# STM32L051T8Y7 register map
File version: 1.0
Registers are 32-bit, access not given, reset 0x0 unless marked. A register's access mark holds for its fields unless they carry their own. Offsets are from the block's base; [hi:lo] are bit positions; {n}, {i} and the like mark numbered series; 'fields as' and 'values as' point back to an identical list.

## LPTIM1
Base 0x40007C00
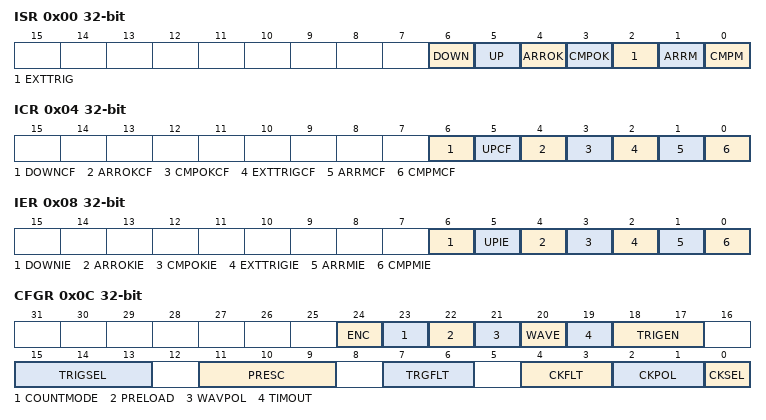
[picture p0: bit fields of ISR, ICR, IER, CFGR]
0x00 ISR
  [6] DOWN, [5] UP, [4] ARROK, [3] CMPOK, [2] EXTTRIG, [1] ARRM, [0] CMPM
0x04 ICR
  [6] DOWNCF, [5] UPCF, [4] ARROKCF, [3] CMPOKCF, [2] EXTTRIGCF, [1] ARRMCF, [0] CMPMCF
0x08 IER
  [6] DOWNIE, [5] UPIE, [4] ARROKIE, [3] CMPOKIE, [2] EXTTRIGIE, [1] ARRMIE, [0] CMPMIE
0x0C CFGR
  [24] ENC, [23] COUNTMODE, [22] PRELOAD, [21] WAVPOL, [20] WAVE, [19] TIMOUT, [18:17] TRIGEN, [15:13] TRIGSEL, [11:9] PRESC, [7:6] TRGFLT, [4:3] CKFLT, [2:1] CKPOL, [0] CKSEL
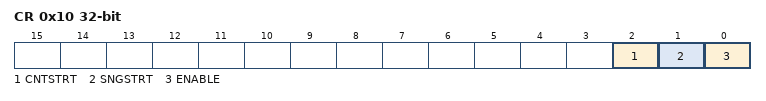
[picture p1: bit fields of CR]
0x10 CR
  [2] CNTSTRT, [1] SNGSTRT, [0] ENABLE
0x14 CMP
  [15:0] CMP
0x18 ARR
  [15:0] ARR
0x1C CNT
  [15:0] CNT

## SYSCFG
Base 0x40010000
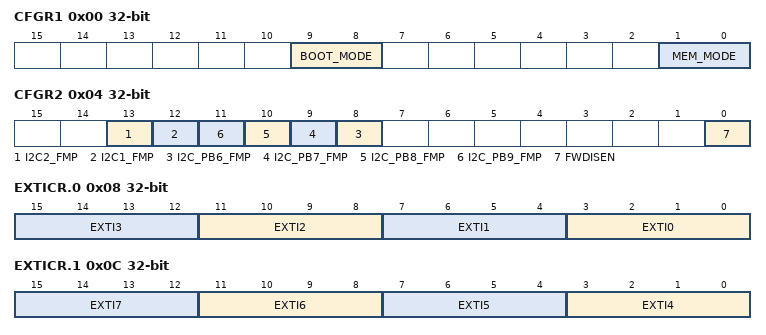
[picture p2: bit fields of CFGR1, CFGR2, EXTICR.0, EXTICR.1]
0x00 CFGR1
  [9:8] BOOT_MODE, [1:0] MEM_MODE
0x04 CFGR2
  [13] I2C2_FMP, [12] I2C1_FMP, [n+2] I2C_PB{n}_FMP (n=6..9), [0] FWDISEN
0x08 EXTICR.0
  [4n+3:4n] EXTI{n} (n=0..3)
0x0C EXTICR.1
  [4n-13:4n-16] EXTI{n} (n=4..7)
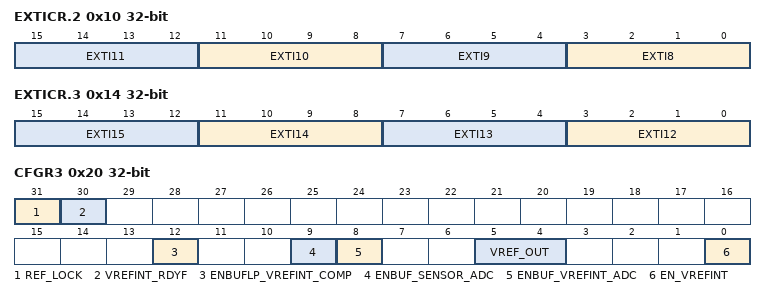
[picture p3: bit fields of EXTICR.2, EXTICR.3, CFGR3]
0x10 EXTICR.2
  [4n-29:4n-32] EXTI{n} (n=8..11)
0x14 EXTICR.3
  [4n-45:4n-48] EXTI{n} (n=12..15)
0x20 CFGR3
  [31] REF_LOCK, [30] VREFINT_RDYF, [12] ENBUFLP_VREFINT_COMP, [9] ENBUF_SENSOR_ADC, [8] ENBUF_VREFINT_ADC, [5:4] VREF_OUT, [0] EN_VREFINT

## COMP12_COMMON
Base 0x40010018
Same registers: COMP1 0x40010018
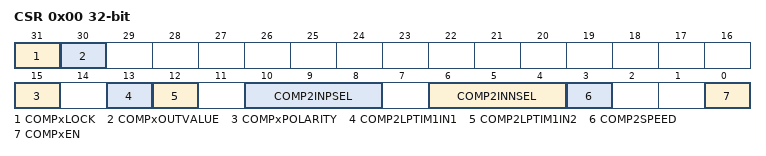
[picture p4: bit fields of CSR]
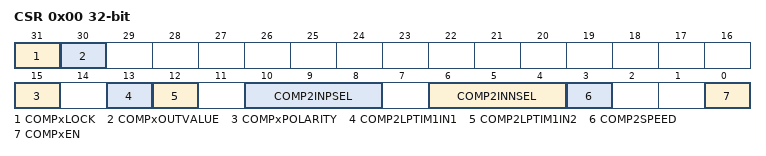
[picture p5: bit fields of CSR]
0x00 CSR
  [31] COMPxLOCK, [30] COMPxOUTVALUE, [15] COMPxPOLARITY, [13] COMP2LPTIM1IN1, [12] COMP2LPTIM1IN2, [10:8] COMP2INPSEL, [6:4] COMP2INNSEL, [3] COMP2SPEED, [0] COMPxEN

## COMP2
Base 0x4001001C
0x00 CSR
  [31] COMPxLOCK, [30] COMPxOUTVALUE, [15] COMPxPOLARITY, [13] COMP2LPTIM1IN1, [12] COMP2LPTIM1IN2, [10:8] COMP2INPSEL, [6:4] COMP2INNSEL, [3] COMP2SPEED, [0] COMPxEN

## EXTI
Base 0x40010400
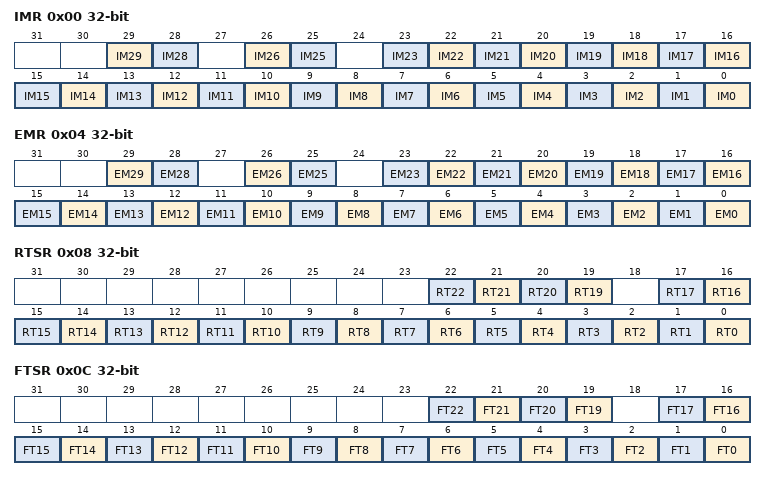
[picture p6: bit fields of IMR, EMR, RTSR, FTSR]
0x00 IMR
  [29] IM29, [28] IM28, [26] IM26, [25] IM25, [n] IM{n} (n=0..23)
0x04 EMR
  [29] EM29, [28] EM28, [26] EM26, [25] EM25, [n] EM{n} (n=0..23)
0x08 RTSR
  [n] RT{n} (n=19..22), [n] RT{n} (n=0..17)
0x0C FTSR
  [n] FT{n} (n=19..22), [n] FT{n} (n=0..17)
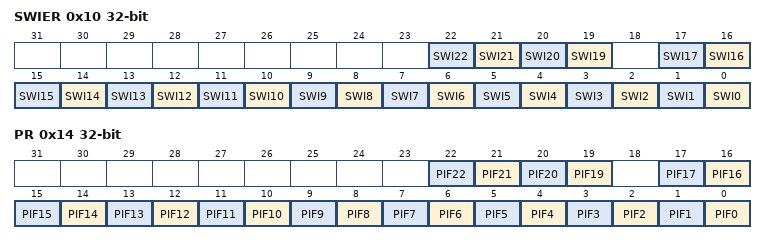
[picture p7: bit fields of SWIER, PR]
0x10 SWIER
  [n] SWI{n} (n=19..22), [n] SWI{n} (n=0..17)
0x14 PR
  [n] PIF{n} (n=19..22), [n] PIF{n} (n=0..17)

## FIREWALL
Base 0x40011C00
0x00 CSSA
0x04 CSL
0x08 NVDSSA
0x0C NVDSL
0x10 VDSSA
0x14 VDSL
0x18 LSSA
0x1C LSL
0x20 CR

## ADC1
Base 0x40012400
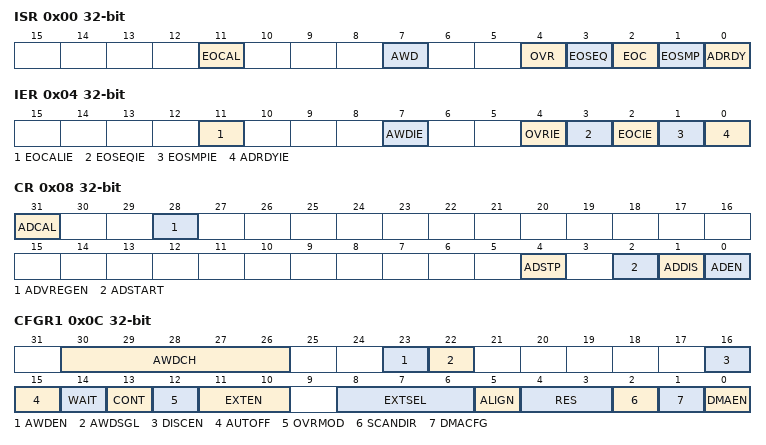
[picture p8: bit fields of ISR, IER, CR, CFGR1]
0x00 ISR
  [11] EOCAL, [7] AWD, [4] OVR, [3] EOSEQ, [2] EOC, [1] EOSMP, [0] ADRDY
0x04 IER
  [11] EOCALIE, [7] AWDIE, [4] OVRIE, [3] EOSEQIE, [2] EOCIE, [1] EOSMPIE, [0] ADRDYIE
0x08 CR
  [31] ADCAL, [28] ADVREGEN, [4] ADSTP, [2] ADSTART, [1] ADDIS, [0] ADEN
0x0C CFGR1
  [30:26] AWDCH, [23] AWDEN, [22] AWDSGL, [16] DISCEN, [15] AUTOFF, [14] WAIT, [13] CONT, [12] OVRMOD, [11:10] EXTEN, [8:6] EXTSEL, [5] ALIGN, [4:3] RES, [2] SCANDIR, [1] DMACFG, [0] DMAEN
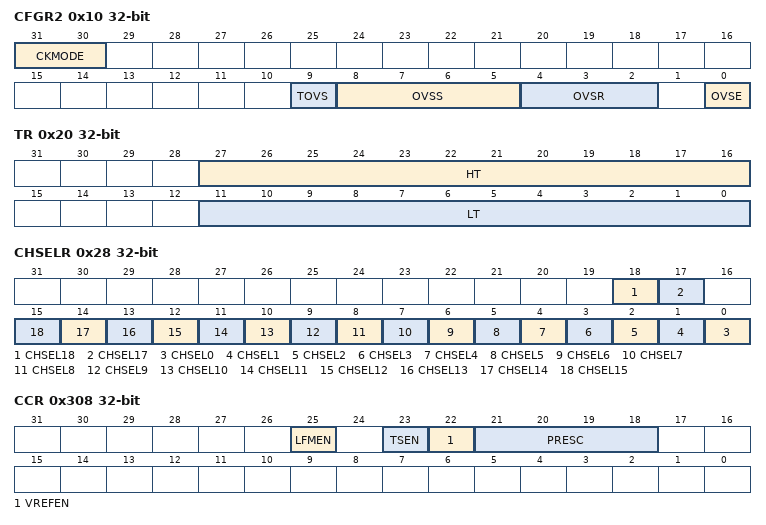
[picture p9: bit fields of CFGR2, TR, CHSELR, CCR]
0x10 CFGR2
  [31:30] CKMODE, [9] TOVS, [8:5] OVSS, [4:2] OVSR, [0] OVSE
0x14 SMPR
  [2:0] SMP
0x20 TR
  [27:16] HT, [11:0] LT
0x28 CHSELR
  [18] CHSEL18, [17] CHSEL17, [n] CHSEL{n} (n=0..15)
0x40 DR
  [15:0] DATA
0xB4 CALFACT
  [6:0] CALFACT
0x308 CCR
  [25] LFMEN, [23] TSEN, [22] VREFEN, [21:18] PRESC

## DMA1
Base 0x40020000
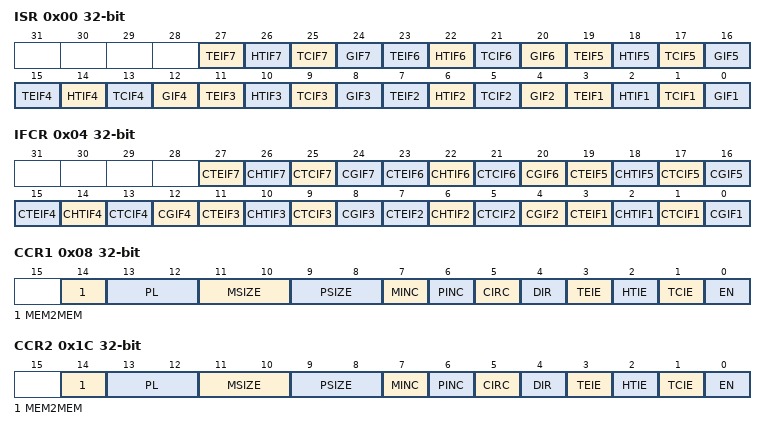
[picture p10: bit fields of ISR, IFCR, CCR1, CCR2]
0x00 ISR
  [4n-1] TEIF{n} (n=1..7), [4n-2] HTIF{n} (n=1..7), [4n-3] TCIF{n} (n=1..7), [4n-4] GIF{n} (n=1..7)
0x04 IFCR
  [4n-1] CTEIF{n} (n=1..7), [4n-2] CHTIF{n} (n=1..7), [4n-3] CTCIF{n} (n=1..7), [4n-4] CGIF{n} (n=1..7)
0x08 CCR1
  [14] MEM2MEM, [13:12] PL, [11:10] MSIZE, [9:8] PSIZE, [7] MINC, [6] PINC, [5] CIRC, [4] DIR, [3] TEIE, [2] HTIE, [1] TCIE, [0] EN
0x0C CNDTR1
  [15:0] NDT
0x10 CPAR1
  [31:0] PA
{0x0+0x14*i} CMAR{i} (i=1..7)
  [31:0] MA
0x1C CCR2
  fields as CCR1
0x20 CNDTR2
  [15:0] NDT
0x24 CPAR2
  [31:0] PA
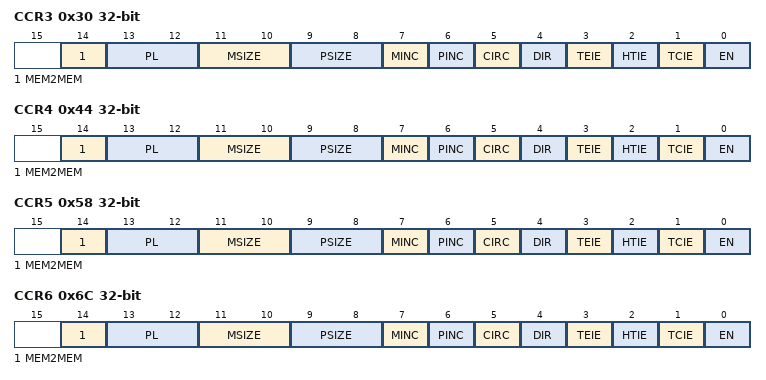
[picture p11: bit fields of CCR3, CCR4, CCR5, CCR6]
0x30 CCR3
  fields as CCR1
0x34 CNDTR3
  [15:0] NDT
0x38 CPAR3
  [31:0] PA
0x44 CCR4
  fields as CCR1
0x48 CNDTR4
  [15:0] NDT
0x4C CPAR4
  [31:0] PA
0x58 CCR5
  fields as CCR1
0x5C CNDTR5
  [15:0] NDT
0x60 CPAR5
  [31:0] PA
0x6C CCR6
  fields as CCR1
0x70 CNDTR6
  [15:0] NDT
0x74 CPAR6
  [31:0] PA
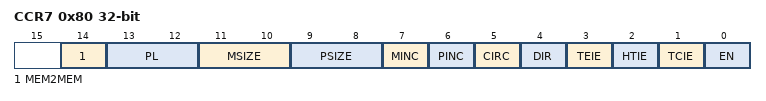
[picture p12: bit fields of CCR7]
0x80 CCR7
  fields as CCR1
0x84 CNDTR7
  [15:0] NDT
0x88 CPAR7
  [31:0] PA
